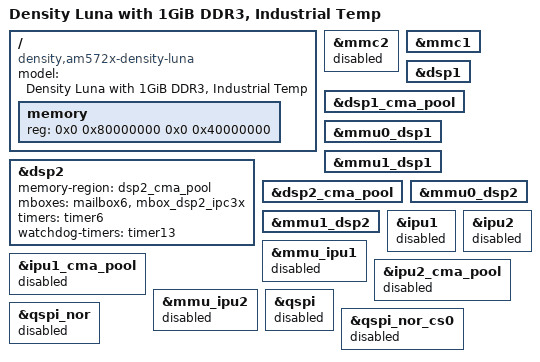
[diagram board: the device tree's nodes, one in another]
/*
 * Copyright (C) 2022 Density, Inc
 *
 */
/dts-v1/;

#include "dra74x.dtsi"

#include "am57xx-density-luna-io.dtsi"      /* Luna I/O - based on am572x-phycore-som.dtsi */
#include "am57xx-density-luna.dtsi"         /* Luna Base - based on am572x-ksp-5015.dtsi */
#include "cmem-dra72x.dtsi"                 /* cmem for dsp/eve */

/ {
	model = "Density Luna with 1GiB DDR3, Industrial Temp";
	compatible = "density,am572x-density-luna", "ti,dra742", "ti,dra74", "ti,dra7";

	memory {
		device_type = "memory";
		reg = <0x0 0x80000000 0x0 0x40000000>; /* 1GiB */
	};
};

/* EMMC */
&mmc2 {
	status = "disabled";
};

/* SD Card */
&mmc1 {
	status = "okay";
};

/* DSP 1 */
&dsp1 {
	status = "okay";
};

&dsp1_cma_pool {
	status = "okay";
};

&mmu0_dsp1 {
	status = "okay";
};

&mmu1_dsp1 {
	status = "okay";
};

/* DSP 2 */
&dsp2 {
	status = "okay";
	memory-region = <&dsp2_cma_pool>;
	mboxes = <&mailbox6 &mbox_dsp2_ipc3x>;
	timers = <&timer6>;
	watchdog-timers = <&timer13>;
};

&dsp2_cma_pool {
	status = "okay";
};

&mmu0_dsp2 {
	status = "okay";
};

&mmu1_dsp2 {
	status = "okay";
};

/* IPU 1 */
&ipu1 {
	status = "disabled";
};

&ipu1_cma_pool {
	status = "disabled";
};

&mmu_ipu1 {
	status = "disabled";
};

/* IPU 2 */
&ipu2 {
	status = "disabled";
};

&ipu2_cma_pool {
	status = "disabled";
};

&mmu_ipu2 {
	status = "disabled";
};

/* SPI */
&qspi {
	status = "disabled";
};

&qspi_nor {
	status = "disabled";
};

&qspi_nor_cs0 {
	status = "disabled";
};
